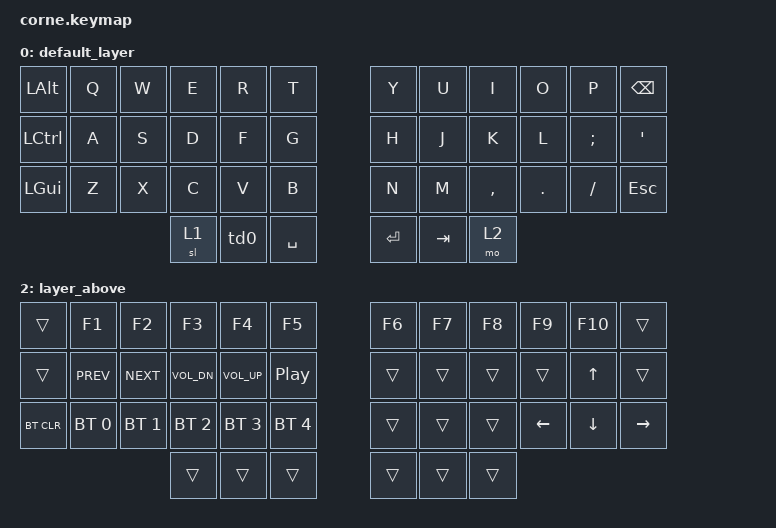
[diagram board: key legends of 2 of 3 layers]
/*
 * Copyright (c) 2020 The ZMK Contributors
 *
 * SPDX-License-Identifier: MIT
 */

#include <behaviors.dtsi>
#include <dt-bindings/zmk/keys.h>
#include <dt-bindings/zmk/bt.h>

/ {
        behaviors {
        td0: tap_dance_0 {
            compatible = "zmk,behavior-tap-dance";
            label = "TAP_DANCE_0";
            #binding-cells = <0>;
            tapping-term-ms = <200>;
            bindings = <&kp LSHFT>, <&kp CAPSLOCK>;
        };
    };

        keymap {
                compatible = "zmk,keymap";

                default_layer {
// -----------------------------------------------------------------------------------------
// |  ALT |  Q  |  W  |  E  |  R  |  T  |   |  Y  |  U   |  I  |  O  |  P  | BKSP | 
// | CTRL |  A  |  S  |  D  |  F  |  G  |   |  H  |  J   |  K  |  L  |  ;  |  '   |
// | GUI |  Z  |  X  |  C  |  V  |  B  |   |  N  |  M   |  ,  |  .  |  /  | ESC  |
//                    | LWR | SHFT | SPC |   | ENT | TAB  | RSE |
                        bindings = <
   &kp LALT   &kp Q &kp W &kp E &kp R &kp T   &kp Y &kp U  &kp I     &kp O   &kp P    &kp BSPC
   &kp LCTRL &kp A &kp S &kp D &kp F &kp G   &kp H &kp J  &kp K     &kp L   &kp SEMI &kp SQT
   &kp LGUI &kp Z &kp X &kp C &kp V &kp B   &kp N &kp M  &kp COMMA &kp DOT &kp FSLH &kp ESC
                    &sl 1 &td0 &kp SPACE   &kp ENTER &kp TAB &mo 2
                        >;
                };

                layer_below {
// -----------------------------------------------------------------------------------------
// |  ALT |  !  |  @  |  #  |  $  |  %  |   |  ^  |  &  |  *  |  (  |  )  |  \   |
// | CTRL |  1  |  2  |  3  |  4  |  5  |   |  -  |  =  |  `  |  [  |  ]  |  "|" |
// | GUI |  6  |  7  |  8  |  9  |  0  |   |  _  |  +  |  ~  |  {  |  }  | ESC  |
//                    |    | SHFT | SPC |   | ENT | TAB  |    |
                        bindings = <
   &kp LALT   &kp EXCL &kp AT &kp HASH &kp DLLR &kp PRCNT   &kp CARET  &kp AMPS  &kp KP_MULTIPLY &kp LPAR &kp RPAR &kp BSLH
   &kp LCTRL &kp N1   &kp N2 &kp N3   &kp N4   &kp N5      &kp MINUS  &kp EQUAL &kp GRAVE       &kp LBKT &kp RBKT &kp PIPE
   &kp GUI &kp N6   &kp N7 &kp N8   &kp N9   &kp N0      &kp UNDER  &kp PLUS  &kp TILDE       &kp LBRC &kp RBRC &kp &trans
                    	&trans &trans  &trans     &trans  &trans  &trans
                        >;
                };

                layer_above {
// -----------------------------------------------------------------------------------------
// |       |  F1  |  F2  |  F3  |  F4  |  F5 |            |  F6  |  F7  |  F8  |  F9  |  F10  |   |
// |       | Prev | Next | Vol - | Vol + | Play/Pause |   |      |    |    |    |  UP  |     |
// | BTCLR | BT1 | BT2 | BT3 | BT4 | BT5 |   |            |     |     |    |   LFT |   DWN  | RGT | 
//                    |     |     |    |                  |     |     |     |
                        bindings = <
   &trans     &kp F1        &kp F2       &kp F3       &kp F4       &kp F5          &kp F6   &kp F7   &kp F8 &kp F9    &kp F10 &trans
   &trans     &kp C_PREV    &kp C_NEXT   &kp C_VOL_DN &kp C_VOL_UP &kp C_PP        &trans &trans  &trans &trans &kp UP &trans
   &bt BT_CLR &bt BT_SEL 0  &bt BT_SEL 1 &bt BT_SEL 2 &bt BT_SEL 3 &bt BT_SEL 4    &trans   &trans &trans  &kp LEFT &kp DOWN   &kp RIGHT 
                                                &trans   &trans   &trans       &trans   &trans   &trans
                        >;
                };
        };
};
